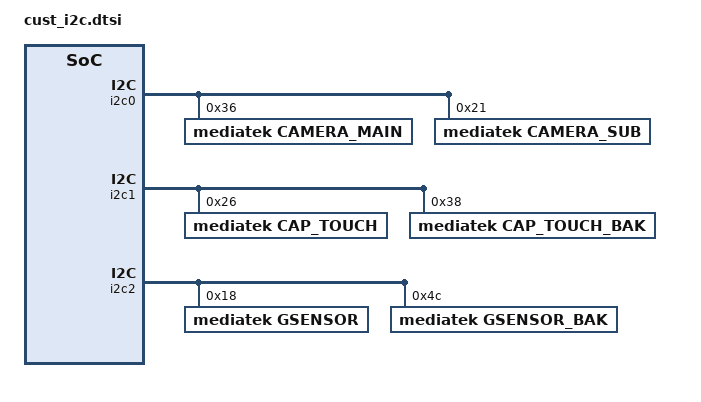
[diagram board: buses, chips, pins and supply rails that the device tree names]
/*
 * Generated by MTK SP Drv_CodeGen Version 03.13.6	for MT6580. Copyright MediaTek Inc. (C) 2013.
 * Wed Dec 11 16:15:46 2019
 * Do Not Modify the File.
 */

/*************************
 * I2C DTSI File
*************************/

&i2c0 {
	#address-cells = <1>;
	#size-cells = <0>;
	camera_main@36 {
		compatible = "mediatek,camera_main";
		reg = <0x36>;
		status = "okay";
	};
	camera_sub@21 {
		compatible = "mediatek,camera_sub";
		reg = <0x21>;
		status = "okay";
	};
};

&i2c1 {
	#address-cells = <1>;
	#size-cells = <0>;
	cap_touch@26 {
		compatible = "mediatek,cap_touch";
		reg = <0x26>;
		status = "okay";
	};
	cap_touch_bak@38 {
		compatible = "mediatek,cap_touch_bak";
		reg = <0x38>;
		status = "okay";
	};
};

&i2c2 {
	#address-cells = <1>;
	#size-cells = <0>;
	gsensor@18 {
		compatible = "mediatek,gsensor";
		reg = <0x18>;
		status = "okay";
	};
	gsensor_bak@4c {
		compatible = "mediatek,gsensor_bak";
		reg = <0x4c>;
		status = "okay";
	};
};

